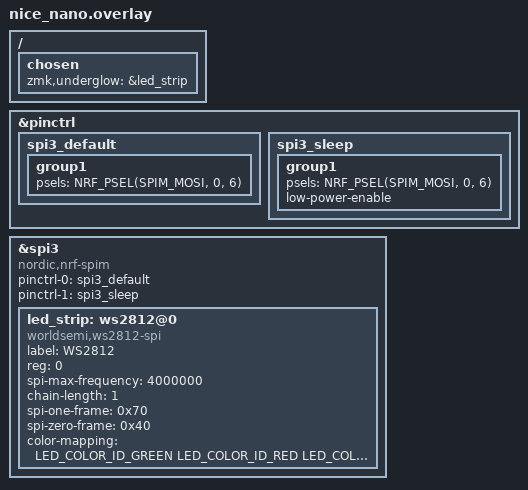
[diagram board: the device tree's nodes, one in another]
/*
 * Nice!Nano v2 overlay for Sofle RGB keyboard
 * 
 * This overlay configures the Nice!Nano for:
 * - Per-key LEDs on the keyboard
 * - Control LED on the left side only (chain-length adjusted accordingly)
 * 
 * Changes made:
 * - Configured LED strip for per-key RGB lighting
 * - Set chain-length to match actual LED count (adjust based on your specific build)
 * - Enabled only left side control LED
 * - Added proper GPIO pin configuration for Nice!Nano v2
 */

#include <dt-bindings/led/led.h>

&pinctrl {
    spi3_default: spi3_default {
        group1 {
            psels = <NRF_PSEL(SPIM_MOSI, 0, 6)>;
        };
    };

    spi3_sleep: spi3_sleep {
        group1 {
            psels = <NRF_PSEL(SPIM_MOSI, 0, 6)>;
            low-power-enable;
        };
    };
};

&spi3 {
    compatible = "nordic,nrf-spim";
    status = "okay";

    pinctrl-0 = <&spi3_default>;
    pinctrl-1 = <&spi3_sleep>;
    pinctrl-names = "default", "sleep";

    led_strip: ws2812@0 {
        compatible = "worldsemi,ws2812-spi";
        label = "WS2812";

        /* SPI */
        reg = <0>; /* ignored, but necessary for SPI binding */
        spi-max-frequency = <4000000>;

        /* WS2812 */
        chain-length = <1>; /* Adjusted for control LED on left side only */
        spi-one-frame = <0x70>;
        spi-zero-frame = <0x40>;

        color-mapping = <LED_COLOR_ID_GREEN LED_COLOR_ID_RED LED_COLOR_ID_BLUE>;
    };
};

/ {
    chosen {
        zmk,underglow = &led_strip;
    };
};
